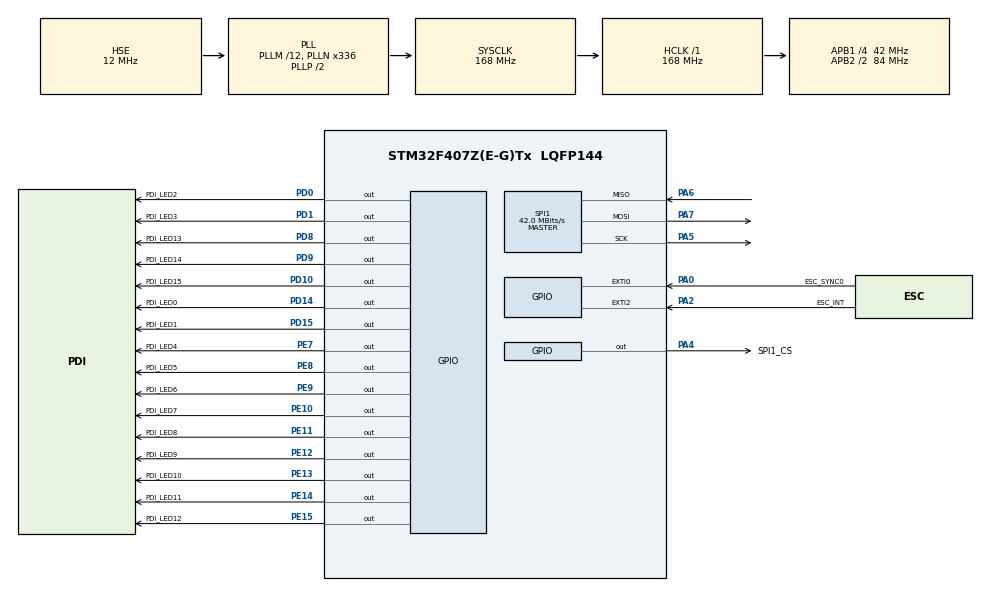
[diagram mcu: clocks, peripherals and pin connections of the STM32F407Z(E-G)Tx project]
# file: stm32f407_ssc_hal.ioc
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Mcu.Family=STM32F4
Mcu.Name=STM32F407Z(E-G)Tx
Mcu.Package=LQFP144
NVIC.EXTI0_IRQn=true\:0\:0\:true\:false\:true\:true\:true\:true
NVIC.EXTI2_IRQn=true\:0\:1\:true\:false\:true\:true\:true\:true
NVIC.PriorityGroup=NVIC_PRIORITYGROUP_2
PA0-WKUP.GPIO_Label=ESC_SYNC0
PA0-WKUP.GPIO_ModeDefaultEXTI=GPIO_MODE_IT_FALLING
PA0-WKUP.GPIO_PuPd=GPIO_PULLUP
PA0-WKUP.Signal=GPXTI0
PA2.GPIO_Label=ESC_INT
PA2.GPIO_ModeDefaultEXTI=GPIO_MODE_IT_FALLING
PA2.GPIO_PuPd=GPIO_PULLUP
PA2.Signal=GPXTI2
PA4.GPIO_Label=SPI1_CS
PA4.GPIO_PuPd=GPIO_PULLUP
PA4.GPIO_Speed=GPIO_SPEED_FREQ_HIGH
PA4.Signal=GPIO_Output
PA5.Mode=Full_Duplex_Master
PA5.Signal=SPI1_SCK
PA6.Mode=Full_Duplex_Master
PA6.Signal=SPI1_MISO
PA7.Mode=Full_Duplex_Master
PA7.Signal=SPI1_MOSI
PD0.GPIO_Label=PDI_LED2
PD0.GPIO_PuPd=GPIO_PULLUP
PD0.GPIO_Speed=GPIO_SPEED_FREQ_HIGH
PD0.Signal=GPIO_Output
PD1.GPIO_Label=PDI_LED3
PD1.GPIO_PuPd=GPIO_PULLUP
PD1.GPIO_Speed=GPIO_SPEED_FREQ_HIGH
PD1.Signal=GPIO_Output
PD10.GPIO_Label=PDI_LED15
PD10.GPIO_PuPd=GPIO_PULLUP
PD10.GPIO_Speed=GPIO_SPEED_FREQ_HIGH
PD10.Signal=GPIO_Output
PD14.GPIO_Label=PDI_LED0
PD14.GPIO_PuPd=GPIO_PULLUP
PD14.GPIO_Speed=GPIO_SPEED_FREQ_HIGH
PD14.Signal=GPIO_Output
PD15.GPIO_Label=PDI_LED1
PD15.GPIO_PuPd=GPIO_PULLUP
PD15.GPIO_Speed=GPIO_SPEED_FREQ_HIGH
PD15.Signal=GPIO_Output
PD8.GPIO_Label=PDI_LED13
PD8.GPIO_PuPd=GPIO_PULLUP
PD8.GPIO_Speed=GPIO_SPEED_FREQ_HIGH
PD8.Signal=GPIO_Output
PD9.GPIO_Label=PDI_LED14
PD9.GPIO_PuPd=GPIO_PULLUP
PD9.GPIO_Speed=GPIO_SPEED_FREQ_HIGH
PD9.Signal=GPIO_Output
PE10.GPIO_Label=PDI_LED7
PE10.GPIO_PuPd=GPIO_PULLUP
PE10.GPIO_Speed=GPIO_SPEED_FREQ_HIGH
PE10.Signal=GPIO_Output
PE11.GPIO_Label=PDI_LED8
PE11.GPIO_PuPd=GPIO_PULLUP
PE11.GPIO_Speed=GPIO_SPEED_FREQ_HIGH
PE11.Signal=GPIO_Output
PE12.GPIO_Label=PDI_LED9
PE12.GPIO_PuPd=GPIO_PULLUP
PE12.GPIO_Speed=GPIO_SPEED_FREQ_HIGH
PE12.Signal=GPIO_Output
PE13.GPIO_Label=PDI_LED10
PE13.GPIO_PuPd=GPIO_PULLUP
PE13.GPIO_Speed=GPIO_SPEED_FREQ_HIGH
PE13.Signal=GPIO_Output
PE14.GPIO_Label=PDI_LED11
PE14.GPIO_PuPd=GPIO_PULLUP
PE14.GPIO_Speed=GPIO_SPEED_FREQ_HIGH
PE14.Signal=GPIO_Output
PE15.GPIO_Label=PDI_LED12
PE15.GPIO_PuPd=GPIO_PULLUP
PE15.GPIO_Speed=GPIO_SPEED_FREQ_HIGH
PE15.Signal=GPIO_Output
PE7.GPIO_Label=PDI_LED4
PE7.GPIO_PuPd=GPIO_PULLUP
PE7.GPIO_Speed=GPIO_SPEED_FREQ_HIGH
PE7.Signal=GPIO_Output
PE8.GPIO_Label=PDI_LED5
PE8.GPIO_PuPd=GPIO_PULLUP
PE8.GPIO_Speed=GPIO_SPEED_FREQ_HIGH
PE8.Signal=GPIO_Output
PE9.GPIO_Label=PDI_LED6
PE9.GPIO_PuPd=GPIO_PULLUP
PE9.GPIO_Speed=GPIO_SPEED_FREQ_HIGH
PE9.Signal=GPIO_Output
PH0-OSC_IN.Mode=HSE-External-Oscillator
PH0-OSC_IN.Signal=RCC_OSC_IN
PH1-OSC_OUT.Mode=HSE-External-Oscillator
PH1-OSC_OUT.Signal=RCC_OSC_OUT
ProjectManager.HeapSize=0x200
ProjectManager.StackSize=0x400
ProjectManager.TargetToolchain=MDK-ARM V5.32
RCC.48MHZClocksFreq_Value=84000000
RCC.AHBFreq_Value=168000000
RCC.APB1CLKDivider=RCC_HCLK_DIV4
RCC.APB1Freq_Value=42000000
RCC.APB1TimFreq_Value=84000000
RCC.APB2CLKDivider=RCC_HCLK_DIV2
RCC.APB2Freq_Value=84000000
RCC.APB2TimFreq_Value=168000000
RCC.CortexFreq_Value=168000000
RCC.HCLKFreq_Value=168000000
RCC.HSE_VALUE=12000000
RCC.HSI_VALUE=16000000
RCC.LSE_VALUE=32768
RCC.PLLM=12
RCC.PLLN=336
RCC.PLLSourceVirtual=RCC_PLLSOURCE_HSE
RCC.SYSCLKFreq_VALUE=168000000
RCC.SYSCLKSource=RCC_SYSCLKSOURCE_PLLCLK
RCC.VCOOutputFreq_Value=336000000
SPI1.BaudRatePrescaler=SPI_BAUDRATEPRESCALER_2
SPI1.CLKPhase=SPI_PHASE_2EDGE
SPI1.CLKPolarity=SPI_POLARITY_HIGH
SPI1.CalculateBaudRate=42.0 MBits/s
SPI1.Direction=SPI_DIRECTION_2LINES
SPI1.Mode=SPI_MODE_MASTER
SPI1.VirtualType=VM_MASTER
TIM3.AutoReloadPreload=TIM_AUTORELOAD_PRELOAD_DISABLE
TIM3.Period=1999
TIM3.Prescaler=84
VP_TIM3_VS_ClockSourceINT.Mode=Internal
board=custom

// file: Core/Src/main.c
/* USER CODE BEGIN Header */
/**
  ******************************************************************************
  * @file           : main.c
  * @brief          : Main program body
  ******************************************************************************
  * @attention
  *
  * Copyright (c) 2024 STMicroelectronics.
  * All rights reserved.
  *
  * This software is licensed under terms that can be found in the LICENSE file
  * in the root directory of this software component.
  * If no LICENSE file comes with this software, it is provided AS-IS.
  *
  ******************************************************************************
  */
/* USER CODE END Header */
#include "main.h"
#include "spi.h"
#include "tim.h"
#include "gpio.h"

/* USER CODE BEGIN Includes */
#include "ecat_def.h"
#include "SSC-Device.h"
#include "applInterface.h"
#include "TR8253Evb.h"
#include "Application.h"
#include "ecat_api.h"
#include "usart.h"
/* USER CODE END Includes */

void SystemClock_Config(void);

int main(void)
{

  /* MCU Configuration--------------------------------------------------------*/

  /* Reset of all peripherals, Initializes the Flash interface and the Systick. */
  HAL_Init();

  /* Configure the system clock */
  SystemClock_Config();

  /* Initialize all configured peripherals */
  MX_GPIO_Init();
  MX_SPI1_Init();
  MX_TIM3_Init();

  /* Infinite loop */
  /* USER CODE BEGIN WHILE */
  ECAT_Stack_Init();
  Sensor_UART_Init(115200);
  ECAT_RegisterPeriodicTask(DO_LED_Ctrl);
  ECAT_RegisterSafeOutput(DO_LED_Off);

  while (1)
  {
    Sonar_Task();
    ECAT_Stack_MainLoop();
  }
  /* USER CODE END 3 */
}

void SystemClock_Config(void)
{
  RCC_OscInitTypeDef RCC_OscInitStruct = {0};
  RCC_ClkInitTypeDef RCC_ClkInitStruct = {0};

  /** Configure the main internal regulator output voltage
  */
  __HAL_RCC_PWR_CLK_ENABLE();
  __HAL_PWR_VOLTAGESCALING_CONFIG(PWR_REGULATOR_VOLTAGE_SCALE1);

  /** Initializes the RCC Oscillators according to the specified parameters
  * in the RCC_OscInitTypeDef structure.
  */
  RCC_OscInitStruct.OscillatorType = RCC_OSCILLATORTYPE_HSE;
  RCC_OscInitStruct.HSEState = RCC_HSE_ON;
  RCC_OscInitStruct.PLL.PLLState = RCC_PLL_ON;
  RCC_OscInitStruct.PLL.PLLSource = RCC_PLLSOURCE_HSE;
  RCC_OscInitStruct.PLL.PLLM = 12;
  RCC_OscInitStruct.PLL.PLLN = 336;
  RCC_OscInitStruct.PLL.PLLP = RCC_PLLP_DIV2;
  RCC_OscInitStruct.PLL.PLLQ = 4;
  if (HAL_RCC_OscConfig(&RCC_OscInitStruct) != HAL_OK)
  {
    Error_Handler();
  }

  /** Initializes the CPU, AHB and APB buses clocks
  */
  RCC_ClkInitStruct.ClockType = RCC_CLOCKTYPE_HCLK|RCC_CLOCKTYPE_SYSCLK
                              |RCC_CLOCKTYPE_PCLK1|RCC_CLOCKTYPE_PCLK2;
  RCC_ClkInitStruct.SYSCLKSource = RCC_SYSCLKSOURCE_PLLCLK;
  RCC_ClkInitStruct.AHBCLKDivider = RCC_SYSCLK_DIV1;
  RCC_ClkInitStruct.APB1CLKDivider = RCC_HCLK_DIV4;
  RCC_ClkInitStruct.APB2CLKDivider = RCC_HCLK_DIV2;

  if (HAL_RCC_ClockConfig(&RCC_ClkInitStruct, FLASH_LATENCY_5) != HAL_OK)
  {
    Error_Handler();
  }
}

void Error_Handler(void)
{
  __disable_irq();
  while (1)
  {
  }
}
